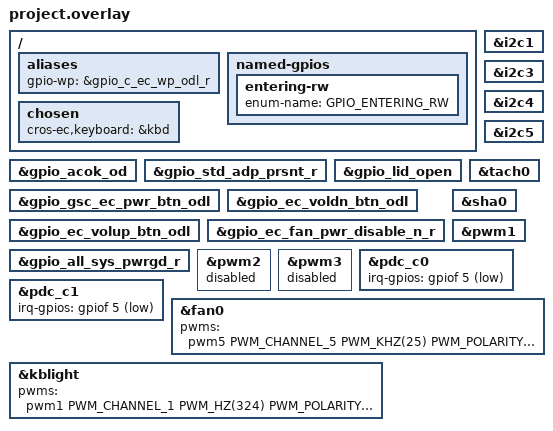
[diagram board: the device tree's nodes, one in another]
/* Copyright 2025 The ChromiumOS Authors
 * Use of this source code is governed by a BSD-style license that can be
 * found in the LICENSE file.
 */

/* ocelot program common DTS includes */

#include <cros/integrated_fwid.dtsi>

/* ocelotrvp-ite project DTS includes */

#include "generated.dtsi"

/*
 * Map I2C buses to common names
 */

i2c_port_pd1: &i2c1 {};
i2c_port_pd2: &i2c3 {};
i2c_port_charger: &i2c4 {};
i2c_port_ish: &i2c5 {};

/*
 * Map GPIOs used for interrupts to common names
 */

gpio_acok: &gpio_acok_od {};
gpio_dc_jack_present: &gpio_std_adp_prsnt_r {};
gpio_lid: &gpio_lid_open {};
gpio_pwrbtn: &gpio_gsc_ec_pwr_btn_odl {};
gpio_voldn: &gpio_ec_voldn_btn_odl {};
gpio_volup: &gpio_ec_volup_btn_odl {};
gpio_fan_control: &gpio_ec_fan_pwr_disable_n_r {};
gpio_all_sys_pwr_good: &gpio_all_sys_pwrgd_r {};

/* Map tachometers to common names */
tach_fan0: &tach0 {};

#include "../rvp_usba.dtsi"
#include "../rvp_battery.dtsi"
#include "../rvp_i2c.dtsi"
#include "../rvp_interrupts.dtsi"
#include "../rvp_usbc.dtsi"
#include "../rvp_keyboard.dtsi"
#include "../rvp_fans.dtsi"
#include "../rvp_temp_sensors.dtsi"

/* ocelotrvp-ite overrides follow... */
/ {
	aliases {
		gpio-wp = &gpio_c_ec_wp_odl_r;
	};

	named-gpios {
		/* unimplemented GPIOs */
		entering-rw {
			enum-name = "GPIO_ENTERING_RW";
		};
	};

	chosen {
		cros-ec,keyboard = &kbd;
	};
};

&sha0 {
	status = "okay";
};

&pwm1 {
	status = "okay";
};
&pwm2 {
	status = "disabled";
};
&pwm3 {
	status = "disabled";
};

/* Update board-specific references  */

&pdc_c0 {
	irq-gpios = <&gpiof 5 GPIO_ACTIVE_LOW>;
};

&pdc_c1 {
	irq-gpios = <&gpiof 5 GPIO_ACTIVE_LOW>;
};

&fan0 {
	pwms = <&pwm5 PWM_CHANNEL_5 PWM_KHZ(25) PWM_POLARITY_NORMAL>;
};

&kblight {
	pwms = <&pwm1 PWM_CHANNEL_1 PWM_HZ(324) PWM_POLARITY_NORMAL>;
};
